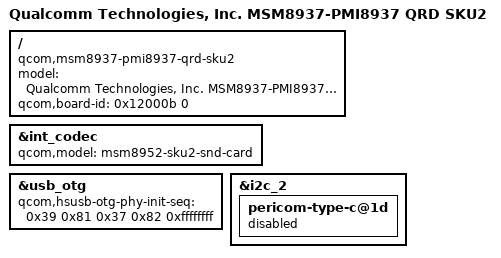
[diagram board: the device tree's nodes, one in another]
/*
 * Copyright (c) 2015-2016, The Linux Foundation. All rights reserved.
 *
 * This program is free software; you can redistribute it and/or modify
 * it under the terms of the GNU General Public License version 2 and
 * only version 2 as published by the Free Software Foundation.
 *
 * This program is distributed in the hope that it will be useful,
 * but WITHOUT ANY WARRANTY; without even the implied warranty of
 * MERCHANTABILITY or FITNESS FOR A PARTICULAR PURPOSE.  See the
 * GNU General Public License for more details.
 */

/dts-v1/;

#include "msm8937.dtsi"
#include "msm8937-pmi8937-qrd-sku2.dtsi"

/ {
	model = "Qualcomm Technologies, Inc. MSM8937-PMI8937 QRD SKU2";
	compatible = "qcom,msm8937-pmi8937-qrd-sku2",
		   "qcom,msm8937-qrd", "qcom,msm8937", "qcom,qrd";
	qcom,board-id= <0x12000b 0>;
};

&int_codec {
	qcom,model = "msm8952-sku2-snd-card";
};

&usb_otg {
	qcom,hsusb-otg-phy-init-seq =
		<0x39 0x81 0x37 0x82 0xffffffff>;
};

&i2c_2 {
	pericom-type-c@1d {
		status="disabled";
	};
};
